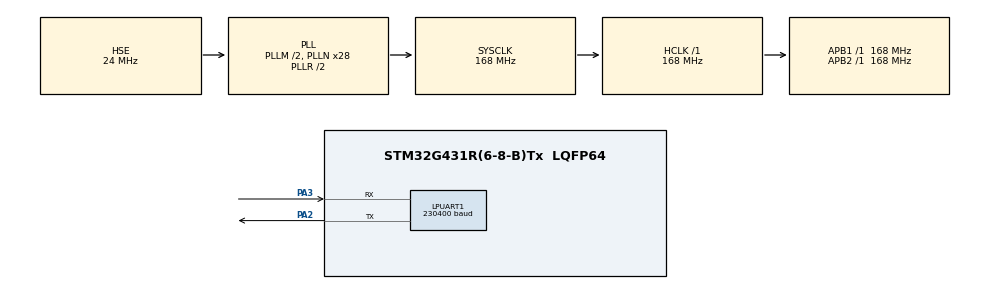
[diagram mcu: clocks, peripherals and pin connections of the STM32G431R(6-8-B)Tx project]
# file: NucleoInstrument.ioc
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FREERTOS.Queues01=COMRxQueue,16,COMEvent_t,0,Dynamic,NULL,NULL;COMEventQueue,16,COMEvent_t,0,Dynamic,NULL,NULL
FREERTOS.Tasks01=COMTask,32,128,StartCOMTask,Default,NULL,Dynamic,NULL,NULL;ParserTask,24,350,StartParserTask,Default,NULL,Dynamic,NULL,NULL
FREERTOS.configCHECK_FOR_STACK_OVERFLOW=2
FREERTOS.configENABLE_FPU=1
FREERTOS.configGENERATE_RUN_TIME_STATS=1
FREERTOS.configRECORD_STACK_HIGH_ADDRESS=1
FREERTOS.configTOTAL_HEAP_SIZE=4096
FREERTOS.configUSE_MALLOC_FAILED_HOOK=0
LPUART1.BaudRate=230400
Mcu.Family=STM32G4
Mcu.Name=STM32G431R(6-8-B)Tx
Mcu.Package=LQFP64
NUCLEO-G431RB.BUTTON=1
NUCLEO-G431RB.LD1=true
NUCLEO-G431RB.VCP=false
NVIC.EXTI15_10_IRQn=true\:5\:0\:false\:false\:true\:true\:false\:true\:true
NVIC.LPUART1_IRQn=true\:5\:0\:false\:false\:true\:true\:true\:true\:true
NVIC.PriorityGroup=NVIC_PRIORITYGROUP_4
NVIC.TIM6_DAC_IRQn=true\:15\:0\:false\:false\:true\:false\:false\:true\:true
NVIC.TimeBase=TIM6_DAC_IRQn
NVIC.TimeBaseIP=TIM6
PA13.GPIO_Label=T_SWDIO
PA13.Signal=SYS_JTMS-SWDIO
PA14.GPIO_Label=T_SWCLK
PA14.Signal=SYS_JTCK-SWCLK
PA2.Mode=Asynchronous
PA2.Signal=LPUART1_TX
PA3.Mode=Asynchronous
PA3.Signal=LPUART1_RX
PB3.GPIO_Label=T_SWO
PB3.Signal=SYS_JTDO-SWO
PC14-OSC32_IN.Mode=LSE-External-Oscillator
PC14-OSC32_IN.Signal=RCC_OSC32_IN
PC15-OSC32_OUT.Mode=LSE-External-Oscillator
PC15-OSC32_OUT.Signal=RCC_OSC32_OUT
PF0-OSC_IN.GPIO_Label=RCC_OSC_IN
PF0-OSC_IN.Mode=HSE-External-Oscillator
PF0-OSC_IN.Signal=RCC_OSC_IN
PF1-OSC_OUT.Mode=HSE-External-Oscillator
PF1-OSC_OUT.Signal=RCC_OSC_OUT
ProjectManager.HeapSize=0x200
ProjectManager.StackSize=0x400
ProjectManager.TargetToolchain=CMake
RCC.ADC12Freq_Value=168000000
RCC.AHBFreq_Value=168000000
RCC.APB1Freq_Value=168000000
RCC.APB1TimFreq_Value=168000000
RCC.APB2Freq_Value=168000000
RCC.APB2TimFreq_Value=168000000
RCC.CortexFreq_Value=168000000
RCC.EXTERNAL_CLOCK_VALUE=12288000
RCC.HCLKFreq_Value=168000000
RCC.HSE_VALUE=24000000
RCC.HSI48_VALUE=48000000
RCC.HSI_VALUE=16000000
RCC.INSTRUCTION_CACHE_ENABLE=1
RCC.PLLM=RCC_PLLM_DIV2
RCC.PLLN=28
RCC.PLLSourceVirtual=RCC_PLLSOURCE_HSE
RCC.RTCClockSelection=RCC_RTCCLKSOURCE_LSE
RCC.SYSCLKFreq_VALUE=168000000
RCC.SYSCLKSource=RCC_SYSCLKSOURCE_PLLCLK
RCC.USBFreq_Value=168000000
RCC.VCOOutputFreq_Value=336000000
VP_FREERTOS_VS_CMSIS_V2.Mode=CMSIS_V2
VP_NUCLEO-G431RB_VS_BSP_COMMON.Mode=COMMON
VP_SYS_VS_DBSignals.Mode=DisableDeadBatterySignals
VP_SYS_VS_tim6.Mode=TIM6
board=NUCLEO-G431RB

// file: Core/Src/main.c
/* USER CODE BEGIN Header */
/**
 ******************************************************************************
 * @file           : main.c
 * @brief          : Main program body
 ******************************************************************************
 * @attention
 *
 * Copyright (c) 2026 STMicroelectronics.
 * All rights reserved.
 *
 * This software is licensed under terms that can be found in the LICENSE file
 * in the root directory of this software component.
 * If no LICENSE file comes with this software, it is provided AS-IS.
 *
 ******************************************************************************
 */
/* USER CODE END Header */
#include "main.h"
#include "cmsis_os.h"
#include "usart.h"
#include "gpio.h"

/* USER CODE BEGIN Includes */
#include "osDefinitions.h"
/* USER CODE END Includes */

void SystemClock_Config(void);
void MX_FREERTOS_Init(void);

int main(void)
{

  /* MCU Configuration--------------------------------------------------------*/

  /* Reset of all peripherals, Initializes the Flash interface and the Systick. */
  HAL_Init();

  /* Configure the system clock */
  SystemClock_Config();

  /* Initialize all configured peripherals */
  MX_GPIO_Init();
  MX_LPUART1_UART_Init();

  /* Init scheduler */
  osKernelInitialize();  /* Call init function for freertos objects (in cmsis_os2.c) */
  MX_FREERTOS_Init();

  /* Initialize leds */
  BSP_LED_Init(LED_GREEN);

  /* Initialize USER push-button, will be used to trigger an interrupt each time it's pressed.*/
  BSP_PB_Init(BUTTON_USER, BUTTON_MODE_EXTI);

  /* Start scheduler */
  osKernelStart();

  /* We should never get here as control is now taken by the scheduler */

  /* Infinite loop */
  while (1) {

  }
}

void SystemClock_Config(void)
{
  RCC_OscInitTypeDef RCC_OscInitStruct = {0};
  RCC_ClkInitTypeDef RCC_ClkInitStruct = {0};

  /** Configure the main internal regulator output voltage
  */
  HAL_PWREx_ControlVoltageScaling(PWR_REGULATOR_VOLTAGE_SCALE1_BOOST);

  /** Initializes the RCC Oscillators according to the specified parameters
  * in the RCC_OscInitTypeDef structure.
  */
  RCC_OscInitStruct.OscillatorType = RCC_OSCILLATORTYPE_HSE;
  RCC_OscInitStruct.HSEState = RCC_HSE_ON;
  RCC_OscInitStruct.PLL.PLLState = RCC_PLL_ON;
  RCC_OscInitStruct.PLL.PLLSource = RCC_PLLSOURCE_HSE;
  RCC_OscInitStruct.PLL.PLLM = RCC_PLLM_DIV2;
  RCC_OscInitStruct.PLL.PLLN = 28;
  RCC_OscInitStruct.PLL.PLLP = RCC_PLLP_DIV2;
  RCC_OscInitStruct.PLL.PLLQ = RCC_PLLQ_DIV2;
  RCC_OscInitStruct.PLL.PLLR = RCC_PLLR_DIV2;
  if (HAL_RCC_OscConfig(&RCC_OscInitStruct) != HAL_OK)
  {
    Error_Handler();
  }

  /** Initializes the CPU, AHB and APB buses clocks
  */
  RCC_ClkInitStruct.ClockType = RCC_CLOCKTYPE_HCLK|RCC_CLOCKTYPE_SYSCLK
                              |RCC_CLOCKTYPE_PCLK1|RCC_CLOCKTYPE_PCLK2;
  RCC_ClkInitStruct.SYSCLKSource = RCC_SYSCLKSOURCE_PLLCLK;
  RCC_ClkInitStruct.AHBCLKDivider = RCC_SYSCLK_DIV1;
  RCC_ClkInitStruct.APB1CLKDivider = RCC_HCLK_DIV1;
  RCC_ClkInitStruct.APB2CLKDivider = RCC_HCLK_DIV1;

  if (HAL_RCC_ClockConfig(&RCC_ClkInitStruct, FLASH_LATENCY_4) != HAL_OK)
  {
    Error_Handler();
  }
}

/* USER CODE BEGIN 4 */
int __io_putchar(int ch) {
  const COMEvent_t TxMsg = {
      .type    = COM_TX_MESSAGE,
      .payload = {ch},
      .length  = 1,
  };
  osMessageQueuePut(COMEventQueueHandle, &TxMsg, 0, osWaitForever);
  return ch;
}
/* USER CODE END 4 */

void HAL_TIM_PeriodElapsedCallback(TIM_HandleTypeDef *htim)
{
  if (htim->Instance == TIM6)
  {
    HAL_IncTick();
  }
}

void Error_Handler(void)
{
  __disable_irq();
  while (1) {
  }
}
#ifdef USE_FULL_ASSERT
/**
  * @brief  Reports the name of the source file and the source line number
  *         where the assert_param error has occurred.
  * @param  file: pointer to the source file name
  * @param  line: assert_param error line source number
  * @retval None
  */
void assert_failed(uint8_t *file, uint32_t line)
{
  /* USER CODE BEGIN 6 */
  /* User can add his own implementation to report the file name and line
     number, ex: printf("Wrong parameters value: file %s on line %d\r\n", file,
     line) */
  /* USER CODE END 6 */
}
#endif /* USE_FULL_ASSERT */

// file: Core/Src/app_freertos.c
/* USER CODE BEGIN Header */
/**
 ******************************************************************************
 * File Name          : app_freertos.c
 * Description        : Code for freertos applications
 ******************************************************************************
 * @attention
 *
 * Copyright (c) 2026 STMicroelectronics.
 * All rights reserved.
 *
 * This software is licensed under terms that can be found in the LICENSE file
 * in the root directory of this software component.
 * If no LICENSE file comes with this software, it is provided AS-IS.
 *
 ******************************************************************************
 */
/* USER CODE END Header */

#include "FreeRTOS.h"
#include "task.h"
#include "main.h"
#include "cmsis_os.h"

/* USER CODE BEGIN Includes */
#include "COM_Task.h"
#include "osDefinitions.h"
#include "scpi_Task.h"
/* USER CODE END Includes */

/* Definitions for COMTask */
osThreadId_t COMTaskHandle;
const osThreadAttr_t COMTask_attributes = {
  .name = "COMTask",
  .priority = (osPriority_t) osPriorityAboveNormal,
  .stack_size = 128 * 4
};
/* Definitions for ParserTask */
osThreadId_t ParserTaskHandle;
const osThreadAttr_t ParserTask_attributes = {
  .name = "ParserTask",
  .priority = (osPriority_t) osPriorityNormal,
  .stack_size = 350 * 4
};
/* Definitions for COMRxQueue */
osMessageQueueId_t COMRxQueueHandle;
const osMessageQueueAttr_t COMRxQueue_attributes = {
  .name = "COMRxQueue"
};
/* Definitions for COMEventQueue */
osMessageQueueId_t COMEventQueueHandle;
const osMessageQueueAttr_t COMEventQueue_attributes = {
  .name = "COMEventQueue"
};

void StartCOMTask(void *argument);
void StartParserTask(void *argument);

void MX_FREERTOS_Init(void); /* (MISRA C 2004 rule 8.1) */

/* Hook prototypes */
void configureTimerForRunTimeStats(void);
unsigned long getRunTimeCounterValue(void);
void vApplicationStackOverflowHook(xTaskHandle xTask, signed char *pcTaskName);

/* USER CODE BEGIN 1 */
/* Functions needed when configGENERATE_RUN_TIME_STATS is on */
__weak void configureTimerForRunTimeStats(void) {}

__weak unsigned long getRunTimeCounterValue(void) { return 0; }
/* USER CODE END 1 */

/* USER CODE BEGIN 4 */
void vApplicationStackOverflowHook(xTaskHandle xTask, signed char *pcTaskName) {
  /* Run time stack overflow checking is performed if
  configCHECK_FOR_STACK_OVERFLOW is defined to 1 or 2. This hook function is
  called if a stack overflow is detected. */
}

/* USER CODE END 4 */

void MX_FREERTOS_Init(void) {

  /* Create the queue(s) */
  /* creation of COMRxQueue */
  COMRxQueueHandle = osMessageQueueNew (16, sizeof(COMEvent_t), &COMRxQueue_attributes);

  /* creation of COMEventQueue */
  COMEventQueueHandle = osMessageQueueNew (16, sizeof(COMEvent_t), &COMEventQueue_attributes);

  /* Create the thread(s) */
  /* creation of COMTask */
  COMTaskHandle = osThreadNew(StartCOMTask, NULL, &COMTask_attributes);

  /* creation of ParserTask */
  ParserTaskHandle = osThreadNew(StartParserTask, NULL, &ParserTask_attributes);

}

void StartCOMTask(void *argument)
{
  /* USER CODE BEGIN StartCOMTask */
  COMTaskInit();

  /* Infinite loop */
  for (;;) {
    COMTaskLoop();
  }
  /* USER CODE END StartCOMTask */
}

void StartParserTask(void *argument)
{
  /* USER CODE BEGIN StartParserTask */
  ParserTaskInit();
  /* Infinite loop */
  for (;;) {
    ParserTaskLoop();
  }
  /* USER CODE END StartParserTask */
}
